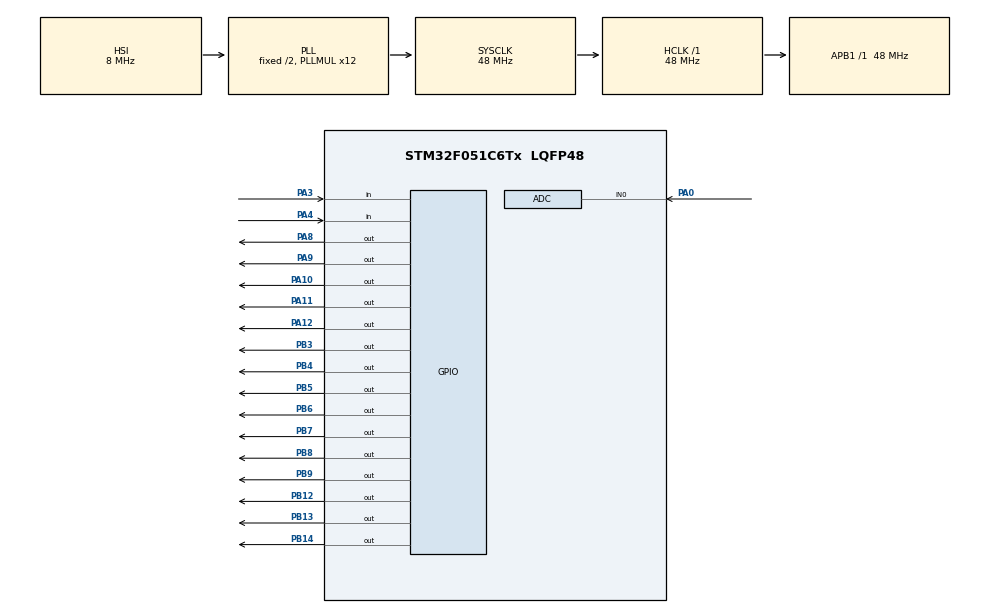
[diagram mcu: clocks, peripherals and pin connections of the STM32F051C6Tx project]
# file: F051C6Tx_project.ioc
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ADC.SamplingTime=ADC_SAMPLETIME_239CYCLES_5
Mcu.Family=STM32F0
Mcu.Name=STM32F051C6Tx
Mcu.Package=LQFP48
NVIC.PVD_IRQn=true\:0\:0\:false\:false\:true\:true\:true
PA0.Mode=IN0
PA0.Signal=ADC_IN0
PA10.GPIO_Speed=GPIO_SPEED_FREQ_LOW
PA10.PinState=GPIO_PIN_SET
PA10.Signal=GPIO_Output
PA11.GPIO_Speed=GPIO_SPEED_FREQ_LOW
PA11.PinState=GPIO_PIN_SET
PA11.Signal=GPIO_Output
PA12.GPIO_Speed=GPIO_SPEED_FREQ_LOW
PA12.PinState=GPIO_PIN_SET
PA12.Signal=GPIO_Output
PA3.GPIO_PuPd=GPIO_PULLDOWN
PA3.Signal=GPIO_Input
PA4.GPIO_PuPd=GPIO_PULLDOWN
PA4.Signal=GPIO_Input
PA8.PinState=GPIO_PIN_SET
PA8.Signal=GPIO_Output
PA9.GPIO_Speed=GPIO_SPEED_FREQ_LOW
PA9.PinState=GPIO_PIN_SET
PA9.Signal=GPIO_Output
PB12.PinState=GPIO_PIN_SET
PB12.Signal=GPIO_Output
PB13.PinState=GPIO_PIN_SET
PB13.Signal=GPIO_Output
PB14.PinState=GPIO_PIN_SET
PB14.Signal=GPIO_Output
PB3.PinState=GPIO_PIN_SET
PB3.Signal=GPIO_Output
PB4.PinState=GPIO_PIN_SET
PB4.Signal=GPIO_Output
PB5.PinState=GPIO_PIN_SET
PB5.Signal=GPIO_Output
PB6.PinState=GPIO_PIN_SET
PB6.Signal=GPIO_Output
PB7.PinState=GPIO_PIN_SET
PB7.Signal=GPIO_Output
PB8.PinState=GPIO_PIN_SET
PB8.Signal=GPIO_Output
PB9.PinState=GPIO_PIN_SET
PB9.Signal=GPIO_Output
PF0-OSC_IN.Mode=HSE-External-Oscillator
PF0-OSC_IN.Signal=RCC_OSC_IN
PF1-OSC_OUT.Mode=HSE-External-Oscillator
PF1-OSC_OUT.Signal=RCC_OSC_OUT
ProjectManager.HeapSize=0x200
ProjectManager.StackSize=0x400
ProjectManager.TargetToolchain=STM32CubeIDE
RCC.AHBFreq_Value=48000000
RCC.APB1Freq_Value=48000000
RCC.APB1TimFreq_Value=48000000
RCC.HCLKFreq_Value=48000000
RCC.PLLMUL=RCC_PLL_MUL12
RCC.SYSCLKFreq_VALUE=48000000
RCC.SYSCLKSource=RCC_SYSCLKSOURCE_PLLCLK
RCC.VDD_VALUE=2.4
board=custom

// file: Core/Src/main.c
/* USER CODE BEGIN Header */
/**
  ******************************************************************************
  * @file           : main.c
  * @brief          : Main program body
  ******************************************************************************
  * @attention
  *
  * <h2><center>&copy; Copyright (c) 2021 STMicroelectronics.
  * All rights reserved.</center></h2>
  *
  * This software component is licensed by ST under BSD 3-Clause license,
  * the "License"; You may not use this file except in compliance with the
  * License. You may obtain a copy of the License at:
  *                        opensource.org/licenses/BSD-3-Clause
  *
  ******************************************************************************
  */
/* USER CODE END Header */
#include "main.h"
#include "./embedded/balloonMachine.h"

ADC_HandleTypeDef hadc;

void SystemClock_Config(void);
static void MX_GPIO_Init(void);
static void MX_ADC_Init(void);

int main(void)
{

  /* MCU Configuration--------------------------------------------------------*/

  /* Reset of all peripherals, Initializes the Flash interface and the Systick. */
  HAL_Init();

  /* Configure the system clock */
  SystemClock_Config();

  /* Initialize all configured peripherals */
  MX_GPIO_Init();
  MX_ADC_Init();

  /* Infinite loop */
  /* USER CODE BEGIN WHILE */

	unsigned int value;
  while (1)
  {

    /* USER CODE END WHILE */
		balloonMachine(&hadc);
  }
}

void SystemClock_Config(void)
{
  RCC_OscInitTypeDef RCC_OscInitStruct = {0};
  RCC_ClkInitTypeDef RCC_ClkInitStruct = {0};

  /** Initializes the RCC Oscillators according to the specified parameters
  * in the RCC_OscInitTypeDef structure.
  */
  RCC_OscInitStruct.OscillatorType = RCC_OSCILLATORTYPE_HSI|RCC_OSCILLATORTYPE_HSI14;
  RCC_OscInitStruct.HSIState = RCC_HSI_ON;
  RCC_OscInitStruct.HSI14State = RCC_HSI14_ON;
  RCC_OscInitStruct.HSICalibrationValue = RCC_HSICALIBRATION_DEFAULT;
  RCC_OscInitStruct.HSI14CalibrationValue = 16;
  RCC_OscInitStruct.PLL.PLLState = RCC_PLL_ON;
  RCC_OscInitStruct.PLL.PLLSource = RCC_PLLSOURCE_HSI;
  RCC_OscInitStruct.PLL.PLLMUL = RCC_PLL_MUL12;
  RCC_OscInitStruct.PLL.PREDIV = RCC_PREDIV_DIV1;
  if (HAL_RCC_OscConfig(&RCC_OscInitStruct) != HAL_OK)
  {
    Error_Handler();
  }
  /** Initializes the CPU, AHB and APB buses clocks
  */
  RCC_ClkInitStruct.ClockType = RCC_CLOCKTYPE_HCLK|RCC_CLOCKTYPE_SYSCLK
                              |RCC_CLOCKTYPE_PCLK1;
  RCC_ClkInitStruct.SYSCLKSource = RCC_SYSCLKSOURCE_PLLCLK;
  RCC_ClkInitStruct.AHBCLKDivider = RCC_SYSCLK_DIV1;
  RCC_ClkInitStruct.APB1CLKDivider = RCC_HCLK_DIV1;

  if (HAL_RCC_ClockConfig(&RCC_ClkInitStruct, FLASH_LATENCY_1) != HAL_OK)
  {
    Error_Handler();
  }
}

static void MX_ADC_Init(void)
{

  ADC_ChannelConfTypeDef sConfig = {0};

  /** Configure the global features of the ADC (Clock, Resolution, Data Alignment and number of conversion)
  */
  hadc.Instance = ADC1;
  hadc.Init.ClockPrescaler = ADC_CLOCK_ASYNC_DIV1;
  hadc.Init.Resolution = ADC_RESOLUTION_12B;
  hadc.Init.DataAlign = ADC_DATAALIGN_RIGHT;
  hadc.Init.ScanConvMode = ADC_SCAN_DIRECTION_FORWARD;
  hadc.Init.EOCSelection = ADC_EOC_SINGLE_CONV;
  hadc.Init.LowPowerAutoWait = DISABLE;
  hadc.Init.LowPowerAutoPowerOff = DISABLE;
  hadc.Init.ContinuousConvMode = DISABLE;
  hadc.Init.DiscontinuousConvMode = DISABLE;
  hadc.Init.ExternalTrigConv = ADC_SOFTWARE_START;
  hadc.Init.ExternalTrigConvEdge = ADC_EXTERNALTRIGCONVEDGE_NONE;
  hadc.Init.DMAContinuousRequests = DISABLE;
  hadc.Init.Overrun = ADC_OVR_DATA_PRESERVED;
  if (HAL_ADC_Init(&hadc) != HAL_OK)
  {
    Error_Handler();
  }
  /** Configure for the selected ADC regular channel to be converted.
  */
  sConfig.Channel = ADC_CHANNEL_0;
  sConfig.Rank = ADC_RANK_CHANNEL_NUMBER;
  sConfig.SamplingTime = ADC_SAMPLETIME_239CYCLES_5;
  if (HAL_ADC_ConfigChannel(&hadc, &sConfig) != HAL_OK)
  {
    Error_Handler();
  }

}

static void MX_GPIO_Init(void)
{
  GPIO_InitTypeDef GPIO_InitStruct = {0};

  /* GPIO Ports Clock Enable */
  __HAL_RCC_GPIOF_CLK_ENABLE();
  __HAL_RCC_GPIOA_CLK_ENABLE();
  __HAL_RCC_GPIOB_CLK_ENABLE();

  /*Configure GPIO pin Output Level */
  HAL_GPIO_WritePin(GPIOB, GPIO_PIN_14, GPIO_PIN_RESET);

	HAL_GPIO_WritePin(GPIOB,GPIO_PIN_3 | GPIO_PIN_4 | GPIO_PIN_5 | GPIO_PIN_6 | GPIO_PIN_7
				| GPIO_PIN_8 | GPIO_PIN_9, GPIO_PIN_RESET);

  HAL_GPIO_WritePin(GPIOB, GPIO_PIN_12, GPIO_PIN_RESET);
	HAL_GPIO_WritePin(GPIOB, GPIO_PIN_13, GPIO_PIN_RESET);

  /*Configure GPIO pin Output Level */
  HAL_GPIO_WritePin(GPIOA, GPIO_PIN_9|GPIO_PIN_10|GPIO_PIN_11
                          |GPIO_PIN_12, GPIO_PIN_SET);

	HAL_GPIO_WritePin(GPIOA,GPIO_PIN_8,GPIO_PIN_RESET);

  /*Configure GPIO pins : PA3 PA4 */
  GPIO_InitStruct.Pin = GPIO_PIN_3|GPIO_PIN_4;
  GPIO_InitStruct.Mode = GPIO_MODE_INPUT;
  GPIO_InitStruct.Pull = GPIO_PULLDOWN;
  HAL_GPIO_Init(GPIOA, &GPIO_InitStruct);

  /*Configure GPIO pins : PB12 PB14 PB3 PB4
                           PB5 PB6 PB7 PB8
                           PB9 */
  GPIO_InitStruct.Pin = GPIO_PIN_12|GPIO_PIN_14| GPIO_PIN_13| GPIO_PIN_3|GPIO_PIN_4
                          |GPIO_PIN_5|GPIO_PIN_6|GPIO_PIN_7|GPIO_PIN_8
                          |GPIO_PIN_9;
  GPIO_InitStruct.Mode = GPIO_MODE_OUTPUT_PP;
  GPIO_InitStruct.Pull = GPIO_NOPULL;
  GPIO_InitStruct.Speed = GPIO_SPEED_FREQ_LOW;
  HAL_GPIO_Init(GPIOB, &GPIO_InitStruct);

  /*Configure GPIO pins : PA8 PA9 PA10 PA11
                           PA12 */
  GPIO_InitStruct.Pin = GPIO_PIN_8|GPIO_PIN_9|GPIO_PIN_10|GPIO_PIN_11
                          |GPIO_PIN_12;
  GPIO_InitStruct.Mode = GPIO_MODE_OUTPUT_PP;
  GPIO_InitStruct.Pull = GPIO_NOPULL;
  GPIO_InitStruct.Speed = GPIO_SPEED_FREQ_LOW;
  HAL_GPIO_Init(GPIOA, &GPIO_InitStruct);

}

void Error_Handler(void)
{
  __disable_irq();
  while (1)
  {
  }
}

/************************ (C) COPYRIGHT STMicroelectronics *****END OF FILE****/
